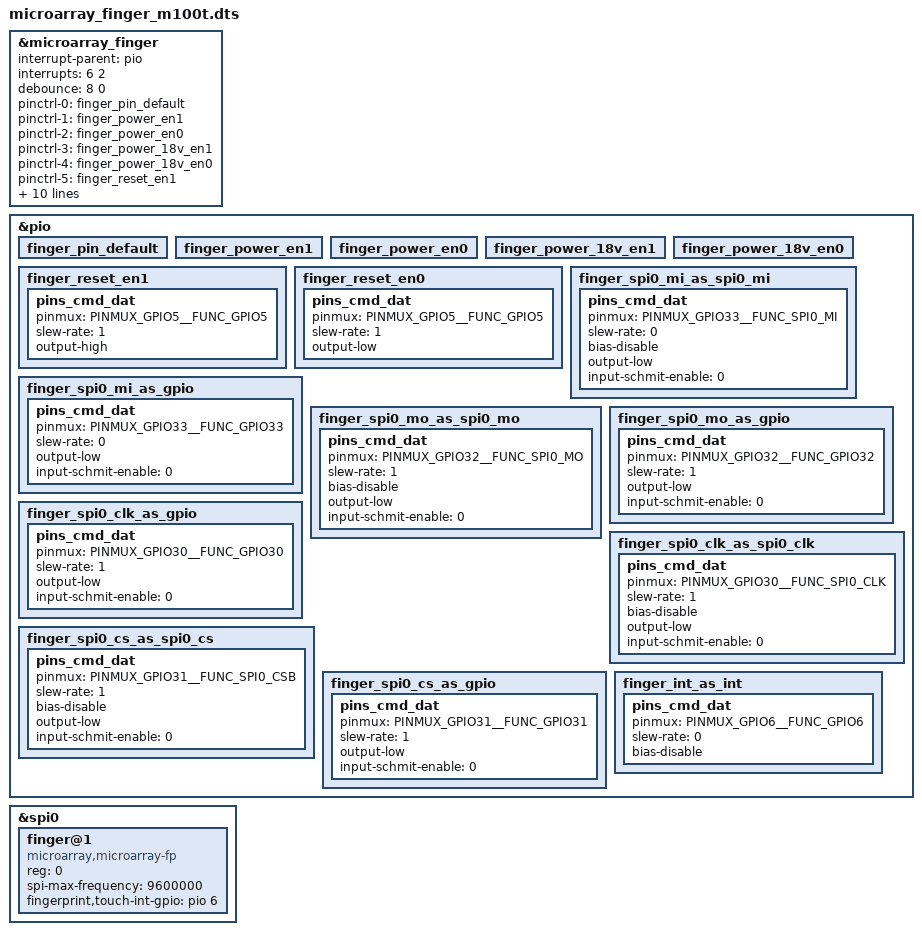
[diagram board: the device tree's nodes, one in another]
/* microarray fingerprint ctrl start */

&microarray_finger {
		interrupt-parent = <&pio>;
		interrupts = <6 2>;
		debounce = <8 0>;
		pinctrl-names = "default", "finger_power_en1", "finger_power_en0","finger_power_18v_en1","finger_power_18v_en0","finger_reset_en1","finger_reset_en0","finger_spi0_mi_as_spi0_mi","finger_spi0_mi_as_gpio","finger_spi0_mo_as_spi0_mo","finger_spi0_mo_as_gpio","finger_spi0_clk_as_spi0_clk","finger_spi0_clk_as_gpio","finger_spi0_cs_as_spi0_cs","finger_spi0_cs_as_gpio", "finger_int_as_int";
		pinctrl-0 = <&finger_pin_default>;
		pinctrl-1 = <&finger_power_en1>;
		pinctrl-2 = <&finger_power_en0>;
		pinctrl-3 = <&finger_power_18v_en1>;
		pinctrl-4 = <&finger_power_18v_en0>;
		pinctrl-5 = <&finger_reset_en1>;
		pinctrl-6 = <&finger_reset_en0>;
		pinctrl-7 = <&finger_spi0_mi_as_spi0_mi>;
		pinctrl-8 = <&finger_spi0_mi_as_gpio>;
		pinctrl-9 = <&finger_spi0_mo_as_spi0_mo>;
		pinctrl-10 = <&finger_spi0_mo_as_gpio>;
		pinctrl-11 = <&finger_spi0_clk_as_spi0_clk>;
		pinctrl-12 = <&finger_spi0_clk_as_gpio>;
		pinctrl-13 = <&finger_spi0_cs_as_spi0_cs>;
		pinctrl-14 = <&finger_spi0_cs_as_gpio>;
		pinctrl-15 = <&finger_int_as_int>;
		status = "okay";
};

&pio {
	finger_pin_default: finger_pin_default {
	};
	finger_power_en1: finger_power_en1 {
	};
	finger_power_en0: finger_power_en0 {
	};

	finger_power_18v_en1: finger_power_18v_en1 {
	};
	finger_power_18v_en0: finger_power_18v_en0 {
	};

	finger_reset_en1: finger_reset_en1 {
		pins_cmd_dat {
			pinmux = <PINMUX_GPIO5__FUNC_GPIO5>;
			slew-rate = <1>;
			output-high;
		};
	};
	finger_reset_en0: finger_reset_en0 {
		pins_cmd_dat {
			pinmux = <PINMUX_GPIO5__FUNC_GPIO5>;
			slew-rate = <1>;
			output-low;
		};
	};

	finger_spi0_mi_as_spi0_mi: finger_spi0_mi_as_spi0_mi {
		pins_cmd_dat {
			pinmux = <PINMUX_GPIO33__FUNC_SPI0_MI>;
			slew-rate = <0>;
			bias-disable;
			output-low;
			input-schmit-enable = <0>;
		};
	};
	finger_spi0_mi_as_gpio: finger_spi0_mi_as_gpio {
		pins_cmd_dat {
			pinmux = <PINMUX_GPIO33__FUNC_GPIO33>;
			slew-rate = <0>;
			output-low;
			input-schmit-enable = <0>;
		};
	};
	finger_spi0_mo_as_spi0_mo: finger_spi0_mo_as_spi0_mo {
		pins_cmd_dat {
			pinmux = <PINMUX_GPIO32__FUNC_SPI0_MO>;
			slew-rate = <1>;
			bias-disable;
			output-low;
			input-schmit-enable = <0>;
		};
	};
	finger_spi0_mo_as_gpio: finger_spi0_mo_as_gpio {
		pins_cmd_dat {
			pinmux = <PINMUX_GPIO32__FUNC_GPIO32>;
			slew-rate = <1>;
			output-low;
			input-schmit-enable = <0>;
		};
	};
	finger_spi0_clk_as_spi0_clk: finger_spi0_clk_as_spi0_clk {
		pins_cmd_dat {
			pinmux = <PINMUX_GPIO30__FUNC_SPI0_CLK>;
			slew-rate = <1>;
			bias-disable;
			output-low;
			input-schmit-enable = <0>;
		};
	};
	finger_spi0_clk_as_gpio: finger_spi0_clk_as_gpio {
		pins_cmd_dat {
			pinmux = <PINMUX_GPIO30__FUNC_GPIO30>;
			slew-rate = <1>;
			output-low;
			input-schmit-enable = <0>;
		};
	};
	finger_spi0_cs_as_spi0_cs: finger_spi0_cs_as_spi0_cs {
		pins_cmd_dat {
			pinmux = <PINMUX_GPIO31__FUNC_SPI0_CSB>;
			slew-rate = <1>;
			bias-disable;
			output-low;
			input-schmit-enable = <0>;
		};
	};
	finger_spi0_cs_as_gpio: finger_spi0_cs_as_gpio {
		pins_cmd_dat {
			pinmux = <PINMUX_GPIO31__FUNC_GPIO31>;
			slew-rate = <1>;
			output-low;
			input-schmit-enable = <0>;
		};
	};
	finger_int_as_int: finger_int_as_int {
		pins_cmd_dat {
			pinmux = <PINMUX_GPIO6__FUNC_GPIO6>;
                        slew-rate = <0>;
                        bias-disable;
		};
	};

};

&spi0 {
	#address-cells = <1>;     
	#size-cells = <0>;
 
    	finger@1 {
       		compatible = "microarray,microarray-fp";
       		reg = <0>;
       		spi-max-frequency = <9600000>;	
        	fingerprint,touch-int-gpio = <&pio 6 0>;
		
       		status = "okay";
    	}; 
};
/* microarray fingerprint ctrl end */
